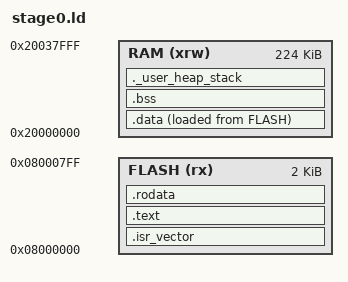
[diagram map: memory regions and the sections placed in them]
ENTRY(Reset_Handler)

_estack = 0x20037FE0;

_Min_Heap_Size = 0x0;
_Min_Stack_Size = 0x100;

MEMORY
{
  FLASH (rx)  : ORIGIN = 0x08000000, LENGTH = 2K
  RAM (xrw)   : ORIGIN = 0x20000000, LENGTH = 224K
}

SECTIONS
{
  .isr_vector :
  {
    . = ALIGN(4);
    KEEP(*(.isr_vector))
    . = ALIGN(4);
  } >FLASH

  .text :
  {
    . = ALIGN(4);
    *(.text)
    *(.text*)
    *(.glue_7)
    *(.glue_7t)
    KEEP (*(.init))
    KEEP (*(.fini))
    . = ALIGN(4);
  } >FLASH

  .rodata :
  {
    . = ALIGN(4);
    *(.rodata)
    *(.rodata*)
    . = ALIGN(4);
  } >FLASH

  _sidata = LOADADDR(.data);

  .data :
  {
    . = ALIGN(4);
    _sdata = .;
    *(.data)
    *(.data*)
    . = ALIGN(4);
    _edata = .;
  } >RAM AT> FLASH

  . = ALIGN(4);
  .bss :
  {
    _sbss = .;
    __bss_start__ = _sbss;
    *(.bss)
    *(.bss*)
    *(COMMON)
    . = ALIGN(4);
    _ebss = .;
    __bss_end__ = _ebss;
  } >RAM

  ._user_heap_stack :
  {
    . = ALIGN(8);
    PROVIDE ( end = . );
    PROVIDE ( _end = . );
    . = . + _Min_Heap_Size;
    . = . + _Min_Stack_Size;
    . = ALIGN(8);
  } >RAM

  /DISCARD/ :
  {
    libc.a ( * )
    libm.a ( * )
    libgcc.a ( * )
    *(.ARM.exidx*)
    *(.ARM.extab*)
  }

  .ARM.attributes 0 : { *(.ARM.attributes) }
}
